AUTOSAR XML (schema 4-2-2)
package /Components
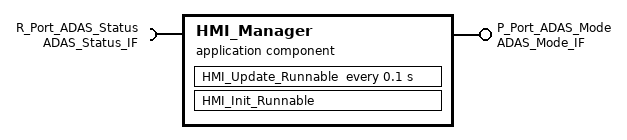
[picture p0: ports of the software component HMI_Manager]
  application sw component type HMI_Manager
    provide port P_Port_ADAS_Mode: provided-interface=ADAS_Mode_IF
    require port R_Port_ADAS_Status: required-interface=ADAS_Status_IF
    behavior HMI_Manager_InternalBehavior
      init event HMI_Init_Event: start-on-event=HMI_Init_Runnable
      timing event HMI_Update_Event: start-on-event=HMI_Update_Runnable, period=0.1
      runnable HMI_Init_Runnable
        parameter access PA_Init_UI_Config_ACC: accessed-parameter=R_Port_ADAS_Status.ACC_Status
        parameter access PA_Init_UI_Config_AEB: accessed-parameter=R_Port_ADAS_Status.AEB_Status
      runnable HMI_Update_Runnable: minimum-start-interval=0.1
        data-receive-point-by-arguments:
          access VA_Recv_ACC_Status: accessed-variable=R_Port_ADAS_Status.ACC_Status
          access VA_Recv_LKA_Status: accessed-variable=R_Port_ADAS_Status.LKA_Status
          access VA_Recv_AEB_Status: accessed-variable=R_Port_ADAS_Status.AEB_Status
        parameter access PA_Run_UI_Config_ACC: accessed-parameter=R_Port_ADAS_Status.ACC_Status
        parameter access PA_Run_UI_Config_LKA: accessed-parameter=R_Port_ADAS_Status.LKA_Status
